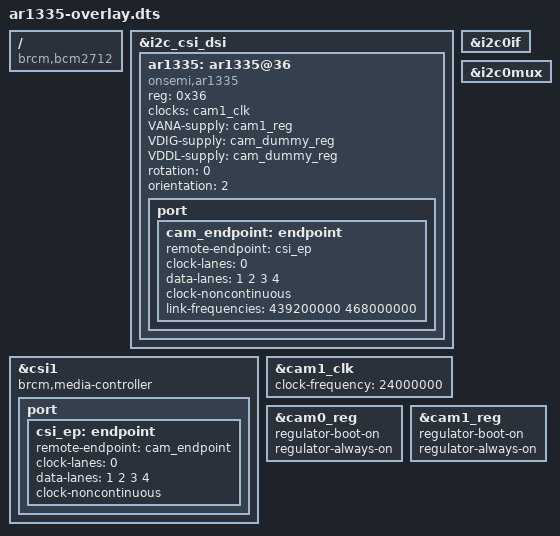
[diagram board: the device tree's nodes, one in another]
// SPDX-License-Identifier: GPL-2.0
/*
 * Device tree overlay for the onsemi AR1335 13 MP camera on Raspberry Pi 5.
 *
 * Defaults to the CAM1 / DISP1 connector; pass the `cam0` parameter to target
 * CAM0 instead. To support a module in *either* port without reconfiguration,
 * load the overlay twice in config.txt:
 *
 *     dtoverlay=ar1335            # CAM1
 *     dtoverlay=ar1335,cam0       # CAM0
 *
 * The driver returns -ENODEV when the chip ID does not read back, so the empty
 * port simply fails to probe and costs nothing.
 *
 * IMPORTANT — sensor enable pin:
 * This board wires the sensor enable to connector GPIO1 (IO1), whereas stock
 * Raspberry Pi wiring uses IO0. The regulator GPIOs must therefore be
 * overridden in config.txt:
 *
 *     dtparam=cam0_reg_gpio=35    # CAM0 IO1 = RP1 line 35
 *     dtparam=cam1_reg_gpio=48    # CAM1 IO1 = RP1 line 48
 *
 * The AR1335 needs a 6-48 MHz EXTCLK to respond on I2C at all. This module has
 * its own 24 MHz oscillator, so cam*_clk below simply declares that frequency
 * to the driver; nothing needs to be generated by the Pi.
 *
 * DO NOT DRIVE CONNECTOR GPIO0 (IO0). On this board IO0 is the module's FLASH
 * output - the module drives it. Driving it from the Pi is output-vs-output
 * contention. CAM0 IO0 = RP1 line 34, CAM1 IO0 = line 46; leave both as
 * inputs. The `extclk` option below muxes IO0 to a clock and must therefore
 * never be enabled on this board.
 */

/dts-v1/;
/plugin/;

/{
	compatible = "brcm,bcm2712";

	/* Sensor on the camera connector's I2C bus. */
	i2c_frag: fragment@0 {
		target = <&i2c_csi_dsi>;
		__overlay__ {
			#address-cells = <1>;
			#size-cells = <0>;
			status = "okay";

			ar1335: ar1335@36 {
				compatible = "onsemi,ar1335";
				reg = <0x36>;
				status = "okay";

				/* Module's own oscillator - see cam*_clk fragment. */
				clocks = <&cam1_clk>;
				clock-names = "xclk";

				/*
				 * VANA is the switched rail / enable line. VDIG and VDDL are
				 * generated on the module itself, so they get the dummy
				 * regulator.
				 */
				VANA-supply = <&cam1_reg>;
				VDIG-supply = <&cam_dummy_reg>;
				VDDL-supply = <&cam_dummy_reg>;

				rotation = <0>;
				orientation = <2>;

				port {
					cam_endpoint: endpoint {
						remote-endpoint = <&csi_ep>;
						clock-lanes = <0>;
						data-lanes = <1 2 3 4>;
						clock-noncontinuous;
						/*
						 * 439.2 MHz: binned 1080p modes (VCO 878.4 MHz)
						 * 468.0 MHz: full-resolution mode (VCO 936 MHz)
						 * Both assume a 24 MHz EXTCLK.
						 */
						link-frequencies =
							/bits/ 64 <439200000 468000000>;
					};
				};
			};
		};
	};

	/* RP1 CSI-2 front end. */
	csi_frag: fragment@1 {
		target = <&csi1>;
		__overlay__ {
			status = "okay";
			brcm,media-controller;

			port {
				csi_ep: endpoint {
					remote-endpoint = <&cam_endpoint>;
					clock-lanes = <0>;
					data-lanes = <1 2 3 4>;
					clock-noncontinuous;
				};
			};
		};
	};

	fragment@2 {
		target = <&i2c0if>;
		__overlay__ {
			status = "okay";
		};
	};

	/* Declares the frequency of the oscillator fitted on the camera module. */
	clk_frag: fragment@3 {
		target = <&cam1_clk>;
		__overlay__ {
			status = "okay";
			clock-frequency = <24000000>;
		};
	};

	fragment@4 {
		target = <&i2c0mux>;
		__overlay__ {
			status = "okay";
		};
	};

	/*
	 * `extclk`: UNSAFE ON THIS BOARD - IO0 is the module's flash output, so
	 * driving a clock onto it is contention. Retained only for a future
	 * module that genuinely lacks an oscillator and leaves IO0 free.
	 *
	 * Have the Pi generate the sensor's EXTCLK instead of relying
	 * on an oscillator fitted to the camera module. The AR1335 has no
	 * internal oscillator and will not even acknowledge its I2C address
	 * without a clock, so this is the fallback for modules that expect the
	 * host to supply one. RP1_CLK_GP3 == 36 in dt-bindings/clock/rp1.h.
	 *
	 * The clock still has to reach the connector's GPIO0 (IO0) pin, which
	 * means muxing that pin to its gpclk3 alt function. That is done from
	 * config.txt rather than here, because this overlay is loaded once per
	 * camera port and two instances would each try to define the same pin
	 * group node:
	 *
	 *     gpio=34=a1     # CAM0 IO0 -> GPCLK3
	 *     gpio=46=a0     # CAM1 IO0 -> GPCLK3
	 *
	 * One generator feeds both pins, so muxing both costs nothing.
	 */
	extclk_frag: fragment@5 {
		target = <&ar1335>;
		__dormant__ {
			clocks = <&rp1_clocks 36>;
			clock-names = "xclk";
			assigned-clocks = <&rp1_clocks 36>;
			assigned-clock-rates = <24000000>;
		};
	};

	/*
	 * Assert the sensor enable from earliest boot and keep it asserted,
	 * rather than only while a driver holds the regulator.
	 *
	 * This matters for power-on-reset ordering. If the module latches its
	 * internal state when 3V3 rises, and its enable is low at that instant,
	 * asserting the enable later never recovers it - only removing power
	 * does. Driving the enable from regulator-core init means that at the
	 * next cold power-up the pin is already high as the rails come up.
	 *
	 * It also makes the steady state simpler: the module is powered, full
	 * stop, instead of being toggled by probe and runtime PM.
	 */
	cam0_reg_frag: fragment@7 {
		target = <&cam0_reg>;
		__overlay__ {
			regulator-boot-on;
			regulator-always-on;
		};
	};

	cam1_reg_frag: fragment@8 {
		target = <&cam1_reg>;
		__overlay__ {
			regulator-boot-on;
			regulator-always-on;
		};
	};

	i2c_slow_frag: fragment@6 {
		target = <&i2c_csi_dsi>;
		__dormant__ {
			clock-frequency = <10000>;
		};
	};

	__overrides__ {
		rotation = <&ar1335>,"rotation:0";
		orientation = <&ar1335>,"orientation:0";

		/* Retarget everything at the CAM0 connector. */
		cam0 = <&i2c_frag>, "target:0=",<&i2c_csi_dsi0>,
		       <&csi_frag>, "target:0=",<&csi0>,
		       <&clk_frag>, "target:0=",<&cam0_clk>,
		       <&ar1335>,   "clocks:0=",<&cam0_clk>,
		       <&ar1335>,   "VANA-supply:0=",<&cam0_reg>,
		       <&i2c_slow_frag>, "target:0=",<&i2c_csi_dsi0>;

		/* Alternate I2C addresses seen on AR1335 modules: 0x10, 0x1a, 0x3c. */
		addr = <&ar1335>, "reg:0";

		/* Oscillator frequency, if the module does not fit a 24 MHz part. */
		clock-frequency = <&clk_frag>,"clock-frequency:0";

		/* Drive EXTCLK from the Pi on connector GPIO0 - see fragment@5. */
		extclk = <0>,"+5";

		/*
		 * `i2c_slow`: drop the camera I2C bus to 10 kHz. A module with weak
		 * pull-ups, a level shifter, or a long FPC can have rise times too
		 * slow for 100 kHz and will then NAK everything.
		 *
		 * This must be a dormant fragment, not a property override: an
		 * override targeting <&i2c_frag> writes onto the *fragment* node,
		 * not into its __overlay__ content, and silently does nothing.
		 */
		i2c_slow = <0>,"+6";
	};
};
